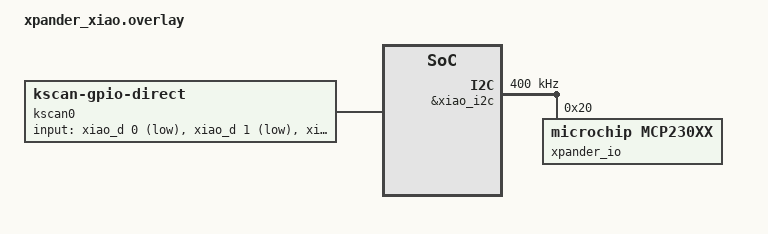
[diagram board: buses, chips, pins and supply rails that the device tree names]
#include <dt-bindings/zmk/matrix_transform.h>

/ {
    chosen {
        zmk,kscan = &kscan0;
        zmk,matrix-transform = &transform0;
    };

    kscan0: kscan {
        compatible = "zmk,kscan-gpio-direct";
        wakeup-source;
        debounce-press-ms = <10>;
        debounce-release-ms = <10>;
        input-gpios
            = <&xiao_d 0 (GPIO_ACTIVE_LOW | GPIO_PULL_UP)>
            , <&xiao_d 1 (GPIO_ACTIVE_LOW | GPIO_PULL_UP)>
            , <&xiao_d 2 (GPIO_ACTIVE_LOW | GPIO_PULL_UP)>
            , <&xiao_d 3 (GPIO_ACTIVE_LOW | GPIO_PULL_UP)>
            , <&xiao_d 4 (GPIO_ACTIVE_LOW | GPIO_PULL_UP)>
            , <&xiao_d 5 (GPIO_ACTIVE_LOW | GPIO_PULL_UP)>
            , <&xiao_d 6 (GPIO_ACTIVE_LOW | GPIO_PULL_UP)>
            , <&xiao_d 7 (GPIO_ACTIVE_LOW | GPIO_PULL_UP)>
            , <&xiao_d 8 (GPIO_ACTIVE_LOW | GPIO_PULL_UP)>
            , <&xpander_io 0 (GPIO_ACTIVE_LOW)>
            , <&xpander_io 1 (GPIO_ACTIVE_LOW)>
            ;
    };

    transform0: keymap_transform {
        compatible = "zmk,matrix-transform";
        columns = <11>;
        rows = <1>;
        map = <
        RC(0,0)  RC(0,1)  RC(0,2)  RC(0,3)  RC(0,4)  RC(0,5)  RC(0,6)  RC(0,7)  RC(0,8)  RC(0,9)  RC(0,10)
        >;
    };

    &xiao_i2c {
    pinctrl-0 = <&sercom2_i2c_default>;
    pinctrl-names = "default";
    status = "okay";
    clock-frequency = <I2C_BITRATE_FAST>;

        xpander_io: mcp23017@20 {
            compatible = "microchip,mcp230xx";
            status = "okay";
            gpio-controller;
            reg = <0x20>; // was 0x20 - should be 0x40? Does address get shifted left by a bit?
            #gpio-cells = <2>;
            ngpios = <16>;
        };
    };
};
